# CH32X035 register map
Vendor: WCH Ltd.; File version: 1.0
Registers are 32-bit, read-write, reset 0x0 unless marked. A register's access mark holds for its fields unless they carry their own. Offsets are from the block's base; [hi:lo] are bit positions; {n}, {i} and the like mark numbered series; 'fields as' and 'values as' point back to an identical list.

## SYSTICK — Systick registers, 64-bit downcounter for QingKeV4
Base 0xE000F000
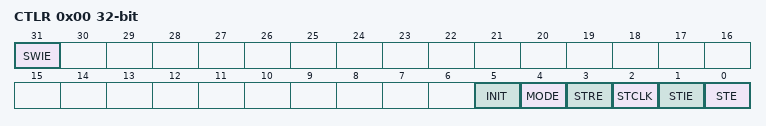
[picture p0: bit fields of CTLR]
0x00 CTLR — System count control register
  [31] SWIE — Software interrupt enable
  [5] INIT — Counter initial value update
  [4] MODE — Counter mode
    0=Upcount; 1=Downcount
  [3] STRE — Auto reload count enable bit
  [2] STCLK — Counter system clock sourse selection bit
    0=HCLK_DIV8 (HCLK/8); 1=HCLK
  [1] STIE — Counter interrupt enable control bit
  [0] STE — Counter enable control bit
0x04 SR — System count status register
  [0] CNTIF — Count value compare flag
0x08 CNT 64-bit (reset mask 0xFFFFFFFF) — System counter register
0x08 CNTL — System counter register, lower 32-bit
0x10 CMP 64-bit (reset mask 0xFFFFFFFF) — System count compare register
0x10 CMPL — System count compare register, lower 32-bit

## AWU — AWU configuration
Base 0x40026400
0x00 AWU_CSR 16-bit — Status Control register
  [1] AWUEN — AWU Enable
0x04 AWU_WR 16-bit reset 0x3F — AWU Window register
  [5:0] AWU_APR — AWU_APR value
0x08 AWU_PSC 16-bit — R16_AWU_PSC
  [3:0] AWU_TBR — AWU_TBR value

## PIOC — PIOC registers
Base 0x40026C00
0x03 STATUS 8-bit ro — SFR_STATUS_REG
0x04 INDIR_ADDR 8-bit — PIOC indirect address register
0x05 TMR0_COUNT 8-bit — PIOC timer0 count register
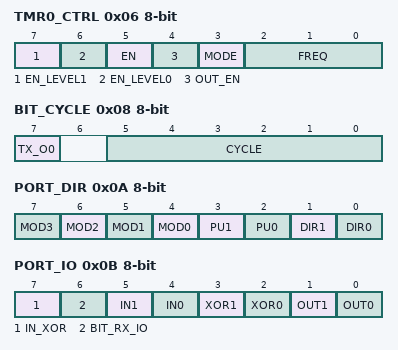
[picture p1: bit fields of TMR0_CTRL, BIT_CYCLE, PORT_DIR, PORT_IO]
0x06 TMR0_CTRL 8-bit — PIOC timer0 control register
  [7] EN_LEVEL1, [6] EN_LEVEL0, [5] EN, [4] OUT_EN, [3] MODE, [2:0] FREQ
0x07 TMR0_INIT 8-bit — PIOC timer0 initial value register
0x08 BIT_CYCLE 8-bit — PIOC bit cycle register
  [7] TX_O0, [5:0] CYCLE
0x09 INDIR_ADDR2 8-bit — PIOC indirect address register2
0x0A PORT_DIR 8-bit — PIOC port direction register
  [n+4] MOD{n} (n=0..3), [3] PU1, [2] PU0, [1] DIR1, [0] DIR0
0x0B PORT_IO 8-bit — PIOC port input/output register
  [7] IN_XOR, [6] BIT_RX_IO, [5] IN1, [4] IN0, [3] XOR1, [2] XOR0, [1] OUT1, [0] OUT0
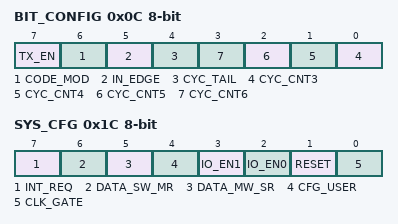
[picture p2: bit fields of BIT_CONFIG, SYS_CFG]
0x0C BIT_CONFIG 8-bit — PIOC bit configuration register
  [7] TX_EN — TX_EN, 编码位的发送使能
  [6] CODE_MOD — CODE_MOD, 编码位的调制方式
  [5] IN_EDGE — IN_EDGE, 引脚输入电平采样时点选择
  [4] CYC_TAIL
  [n-3] CYC_CNT{n} (n=3..6)
0x1C SYS_CFG 8-bit — PIOC system configuration register
  [7] INT_REQ — INT_REQ, int request
  [6] DATA_SW_MR — DATA_SW_MR, slave eMCU wating master to read
  [5] DATA_MW_SR — DATA_MW_SR, master wating slave eMCU to read
  [4] CFG_USER — CFG_USER, user defined
  [3] IO_EN1
  [2] IO_EN0
  [1] RESET
  [0] CLK_GATE — CLK_GATE, eMCU CLK gate enable
0x1D CTRL_RD 8-bit — PIOC control read register
0x1E CTRL_WR 8-bit — PIOC control write register. SFR_CTRL_WR. master read-write, host read-only
0x1F DATA_EXCH 8-bit — PIOC data exchange register
{0x20+i} DATA_REG{i} (i=0..31) 8-bit — PIOC data register{i}

## OPA — OPA configuration
Base 0x40026000
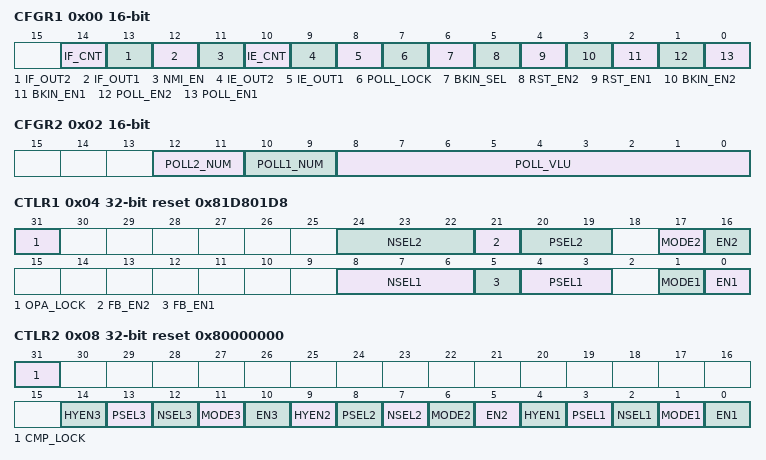
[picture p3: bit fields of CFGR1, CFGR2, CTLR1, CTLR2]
0x00 CFGR1 16-bit — OPA Configuration register
  [14] IF_CNT — IF_CNT Configuration
  [13] IF_OUT2 — IF_OUT2 Enable
  [12] IF_OUT1 — IF_OUT1 Enable
  [11] NMI_EN — NMI_EN Enable
  [10] IE_CNT — IE_CNT Enable
  [9] IE_OUT2 — IE_OUT2 Enable
  [8] IE_OUT1 — IE_OUT1 Enable
  [7] POLL_LOCK — POLL_LOCK select
  [6] BKIN_SEL — BKIN_SEL select
  [5] RST_EN2 — RST_EN2 Enable
  [4] RST_EN1 — RST_EN1 Enable
  [3] BKIN_EN2 — BKIN_EN2 Enable
  [2] BKIN_EN1 — BKIN_EN1 Enable
  [1] POLL_EN2 — POLL_EN2 Enable
  [0] POLL_EN1 — POLL_EN1 Enable
0x02 CFGR2 16-bit access per field — OPA Configuration register
  [12:11] POLL2_NUM wo — POLL2_NUM Configuration
  [10:9] POLL1_NUM wo — POLL1_NUM Configuration
  [8:0] POLL_VLU rw — POLL_VLU Configuration
0x04 CTLR1 reset 0x81D801D8 — OPA Control1 register
  [31] OPA_LOCK
  [24:22] NSEL2 — output select
  [21] FB_EN2 — res inside enable
  [20:19] PSEL2 — Input select
  [17] MODE2 — OPA2 mode
  [16] EN2 — OPA2 enable
  [8:6] NSEL1 — output select
  [5] FB_EN1 — res inside enable
  [4:3] PSEL1 — Input select
  [1] MODE1 — OPA1 mode
  [0] EN1 — OPA1 enable
0x08 CTLR2 reset 0x80000000 — OPA Control2 register
  [31] CMP_LOCK
  [14] HYEN3 — CMP3 HYEN Enable
  [13] PSEL3 — CMP3 IN_P Selection
  [12] NSEL3 — CMP3 IN_N Selection
  [11] MODE3 — CMP3 OUT Selection
  [10] EN3 — CMP3 Enable
  [9] HYEN2 — CMP2 HYEN Enable
  [8] PSEL2 — CMP2 IN_P Selection
  [7] NSEL2 — CMP2 IN_N Selection
  [6] MODE2 — CMP2 OUT Selection
  [5] EN2 — CMP2 Enable
  [4] HYEN1 — CMP1 HYEN Enable
  [3] PSEL1 — CMP1 IN_P Selection
  [2] NSEL1 — CMP1 IN_N Selection
  [1] MODE1 — CMP1 OUT Selection
  [0] EN1 — CMP1 Enable
0x0C OPA_KEY — OPA unlock key register
  [31:0] OPA_KEY — OPA_KEY value
0x10 CMP_KEY — CMP unlock key register
  [31:0] CMP_KEY — CMP_KEY value
0x14 POLL_KEY — POLL unlock key register
  [31:0] POLL_KEY — POLL_KEY value

## ESIG — ESIG configuration
Base 0x1FFFF7E0
0x00 FLACAP 16-bit ro — Flash capecity register
  [15:0] F_SIZE — F_SIZE/kByte
0x08 UNIID1 ro — UID register
  [31:0] U_ID — U_ID value
0x0C UNIID2 ro — UID register
  [31:0] U_ID — U_ID value
0x10 UNIID3 ro — Div register
  [31:0] AWU_APR — AWU_APR value

## USBPD — USBPD configuration
Base 0x40027000
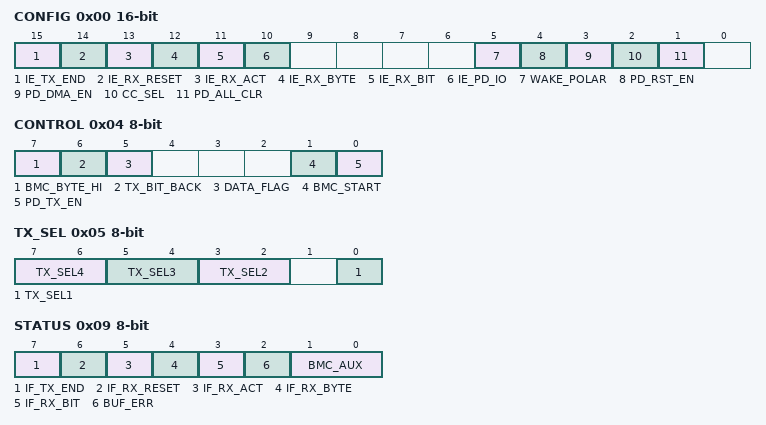
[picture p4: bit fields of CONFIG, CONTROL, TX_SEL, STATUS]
0x00 CONFIG 16-bit — PD interrupt enable register
  [15] IE_TX_END — transfer complete register
  [14] IE_RX_RESET — Receive complete rst register
  [13] IE_RX_ACT — Receive complete register
  [12] IE_RX_BYTE — Receive byte register
  [11] IE_RX_BIT — bit interrupt Enable
  [10] IE_PD_IO — IO Enable
  [5] WAKE_POLAR — wakeup polarity
  [4] PD_RST_EN — PD RST Enable
  [3] PD_DMA_EN — PD DMA Enable
  [2] CC_SEL — PD Commutation port
    0=CC1 (Select CC1); 1=CC2 (Select CC2)
  [1] PD_ALL_CLR — PD ITClear
0x02 BMC_CLK_CNT 16-bit — BMC sampling clock counter
  [8:0] BMC_CLK_CNT — R/T counter
0x04 CONTROL 8-bit access per field — PD Send and receive enable register
  [7] BMC_BYTE_HI ro — BMC_BYTE_HI value
  [6] TX_BIT_BACK ro — TX_BIT_BACK value
  [5] DATA_FLAG ro — DATA_FLAG value
  [1] BMC_START rw — BMC_START value
  [0] PD_TX_EN rw — PD_TX_EN value
0x05 TX_SEL 8-bit — SOP port selection register
  [7:6] TX_SEL4 — TX_SEL4 value
  [5:4] TX_SEL3 — TX_SEL3 value
  [3:2] TX_SEL2 — TX_SEL2 value
  [0] TX_SEL1 — TX_SEL1 value
0x06 BMC_TX_SZ 16-bit — PD send length register
  [8:0] BMC_TX_SZ — BMC_TX_SZ value
0x08 DATA_BUF 8-bit ro — DMA cache data register
  [7:0] DATA_BUF — DATA_BUF value
0x09 STATUS 8-bit — PD interrupt flag register
  [7] IF_TX_END — IF_TX_END value
  [6] IF_RX_RESET — IF_RX_RESET value
  [5] IF_RX_ACT — IF_RX_ACT value
  [4] IF_RX_BYTE — IF_RX_BYTE value
  [3] IF_RX_BIT — IF_RX_BIT value
  [2] BUF_ERR — BUF_ERR value
  [1:0] BMC_AUX — BMC_AUX value
0x0A BMC_BYTE_CNT 16-bit ro — Byte counter
  [8:0] BMC_BYTE_CNT — BMC_BYTE_CNT value
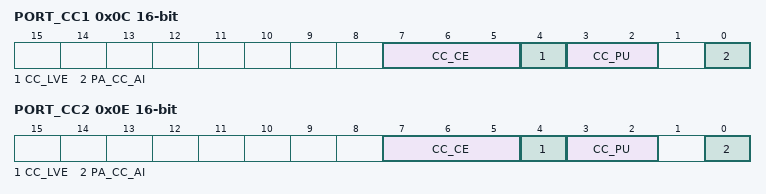
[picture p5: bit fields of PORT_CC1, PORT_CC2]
0x0C PORT_CC1 16-bit access per field — CC1 port control register
  [7:5] CC_CE rw — CC port comparator enable
    0=Closed; 2=V0_22 (0.22V); 3=V0_43 (0.43V); 4=V0_55 (0.55V); 5=V0_66 (0.66V); 6=V0_96 (0.96V); 7=V1_23 (1.23V)
  [4] CC_LVE rw — CC port level 0 voltage
  [3:2] CC_PU rw — CC port pull-up current
    0=Closed (No pull up current); 1=uA330 (330uA); 2=uA180 (180uA); 3=uA80 (80uA)
  [0] PA_CC_AI ro — CC port comparator analog input
0x0E PORT_CC2 16-bit access per field — CC2 port control register
  fields as PORT_CC1
0x10 DMA 16-bit — PD buffer start address register
  [15:0] USBPD_DMA_ADDR — USBPD_DMA_ADDR value
